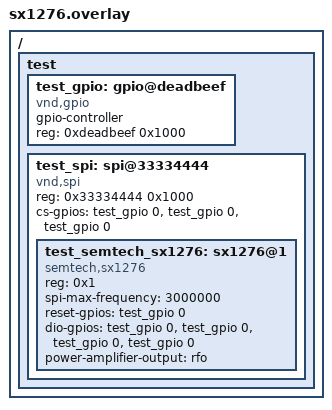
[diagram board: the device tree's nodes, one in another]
/*
 * Copyright (c) 2024 TOKITA Hiroshi
 * SPDX-License-Identifier: Apache-2.0
 */

/ {
	test {
		#address-cells = <1>;
		#size-cells = <1>;

		test_gpio: gpio@deadbeef {
			compatible = "vnd,gpio";
			gpio-controller;
			reg = <0xdeadbeef 0x1000>;
			#gpio-cells = <0x2>;
			status = "okay";
		};

		test_spi: spi@33334444 {
			#address-cells = <1>;
			#size-cells = <0>;
			compatible = "vnd,spi";
			reg = <0x33334444 0x1000>;
			status = "okay";

			cs-gpios = <&test_gpio 0 0>,
			<&test_gpio 0 0>,
			<&test_gpio 0 0>;

			test_semtech_sx1276: sx1276@1 {
				compatible = "semtech,sx1276";
				status = "okay";
				reg = <0x1>;
				spi-max-frequency = <3000000>;

				reset-gpios = <&test_gpio 0 0>;

				dio-gpios = <&test_gpio 0 0>,
					    <&test_gpio 0 0>,
					    <&test_gpio 0 0>,
					    <&test_gpio 0 0>;

				power-amplifier-output = "rfo";
			};
		};
	};
};
